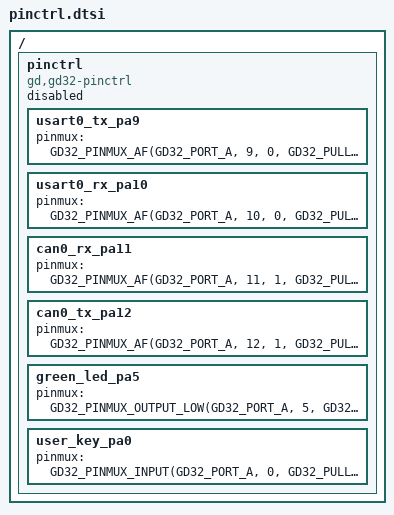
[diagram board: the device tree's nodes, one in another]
/* Reference pin wiring; consumers choose their default state. */
/ {
    pinctrl: pinctrl {
        status = "disabled";
        compatible = "gd,gd32-pinctrl";

        usart0_tx_pa9: usart0_tx_pa9 {
            pinmux = <GD32_PINMUX_AF(GD32_PORT_A, 9, 0,
                                      GD32_PULL_NONE,
                                      GD32_DRIVE_PUSH_PULL, 3)>;
        };

        usart0_rx_pa10: usart0_rx_pa10 {
            pinmux = <GD32_PINMUX_AF(GD32_PORT_A, 10, 0,
                                      GD32_PULL_UP,
                                      GD32_DRIVE_PUSH_PULL, 3)>;
        };

        can0_rx_pa11: can0_rx_pa11 {
            pinmux = <GD32_PINMUX_AF(GD32_PORT_A, 11, 1,
                                      GD32_PULL_UP,
                                      GD32_DRIVE_PUSH_PULL, 3)>;
        };

        can0_tx_pa12: can0_tx_pa12 {
            pinmux = <GD32_PINMUX_AF(GD32_PORT_A, 12, 1,
                                      GD32_PULL_NONE,
                                      GD32_DRIVE_PUSH_PULL, 3)>;
        };

        green_led_pa5: green_led_pa5 {
            pinmux = <GD32_PINMUX_OUTPUT_LOW(GD32_PORT_A, 5,
                                             GD32_PULL_NONE,
                                             GD32_DRIVE_PUSH_PULL, 2)>;
        };

        user_key_pa0: user_key_pa0 {
            pinmux = <GD32_PINMUX_INPUT(GD32_PORT_A, 0,
                                        GD32_PULL_UP, 0)>;
        };
    };
};
